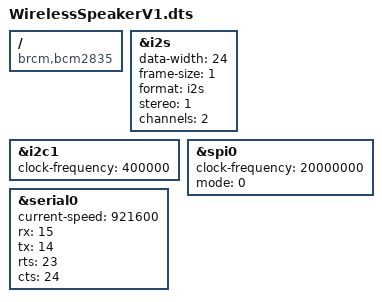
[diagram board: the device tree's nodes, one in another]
/dts-v1/;
/plugin/;

/ {
    compatible = "brcm,bcm2835"; // compatible with all Pi's !

    // I2S
    fragment@0 {
        target = <&i2s>;
        __overlay__ {
            status = "okay";
            data-width = <24>; // 24b audio.
            frame-size = <1>; // One word per channel per LRLCK.
            format = "i2s"; // I2S formated data. If changed, change also the DAC config.
            stereo = <1>; // Redondant
            channels = <2>; // Stereo
        };
    };

    // I2C
    fragment@1 {
        target = <&i2c1>;
        __overlay__ {
            status = "okay";
            clock-frequency = <400000>; // 400 kHz, supported by all devices.
        };
    };

    // SPI
    fragment@2 {
        target = <&spi0>;
        __overlay__ {
            status = "okay";
            clock-frequency = <20000000>; // 20 MHz.
            mode = <0>; // MODE 0 : CPOL = 0 & CPHA = 0;
        };
    };

    // UART0
    fragment@3 {
        target = <&serial0>;
        __overlay__ {
            status = "okay";
            current-speed = <921600>; // 921.6 Mbaud. IC support 3M.
            rx = <15>; // RX standard RPi Pin.
            tx = <14>; // TX standard RPi Pin.
            rts = <23>; // RTS on pin 23. Not standard.
            cts = <24>; // CTS on pin 24. Not standard.
        };
    };

};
